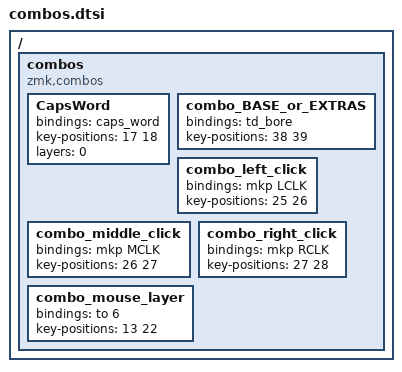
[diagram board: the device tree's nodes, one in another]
/ {
    combos {
        compatible = "zmk,combos";

        CapsWord {
            bindings = <&caps_word>;
            key-positions = <17 18>;
            layers = <0>;
        };

        combo_BASE_or_EXTRAS {
            bindings = <&td_bore>;
            key-positions = <38 39>;
        };
        
        combo_left_click {
            bindings = <&mkp LCLK>;
            key-positions = <25 26>;
        };
        
        combo_middle_click {
            bindings = <&mkp MCLK>;
            key-positions = <26 27>;
        };

        combo_right_click {
            bindings = <&mkp RCLK>;
            key-positions = <27 28>;
        };

        combo_mouse_layer {
            bindings = <&to 6>;
            key-positions = <13 22>;
        };





        // // Left Side Home Row Mods
        // combo_l_cmd {
        //     bindings = <&kp LCMD>;
        //     key-positions = <13 37>;
        //     layers = <0>;
        // };

        // combo_l_alt {
        //     bindings = <&kp LEFT_ALT>;
        //     key-positions = <14 37>;
        //     layers = <0>;
        // };

        // combo_l_ctrl {
        //     bindings = <&kp LCTRL>;
        //     key-positions = <15 37>;
        //     layers = <0>;
        // };

        // combo_l_shift {
        //     bindings = <&kp LEFT_SHIFT>;
        //     key-positions = <16 37>;
        //     layers = <0>;
        // };

        // combo_l_ctrl_alt {
        //     bindings = <&kp LC(LALT)>;
        //     key-positions = <15 15 37>;
        //     layers = <0>;
        // };

        // combo_l_ctrl_shift {
        //     bindings = <&kp LC(LSHFT)>;
        //     key-positions = <15 16 37>;
        //     layers = <0>;
        // };

        // combo_l_ctrl_cmd {
        //     bindings = <&kp LC(LCMD)>;
        //     key-positions = <15 13 37>;
        //     layers = <0>;
        // };

        // combo_l_alt_shift {
        //     bindings = <&kp LA(LSHFT)>;
        //     key-positions = <14 16 37>;
        //     layers = <0>;
        // };

        // combo_l_alt_cmd {
        //     bindings = <&kp LA(LCMD)>;
        //     key-positions = <14 13 37>;
        //     layers = <0>;
        // };

        // combo_l_shift_cmd {
        //     bindings = <&kp LS(LCMD)>;
        //     key-positions = <16 13 37>;
        //     layers = <0>;
        // };

        // combo_l_ctrl_alt_shift {
        //     bindings = <&kp LC(LA(LSHFT))>;
        //     key-positions = <26 37>;
        //     layers = <0>;
        // };

        // combo_l_ctrl_alt_cmd {
        //     bindings = <&kp LC(LA(LCMD))>;
        //     key-positions = <15 14 13 37>;
        //     layers = <0>;
        // };

        // combo_l_ctrl_shift_cmd {
        //     bindings = <&kp LC(LS(LCMD))>;
        //     key-positions = <15 16 13 37>;
        //     layers = <0>;
        // };

        // combo_l_alt_shift_cmd {
        //     bindings = <&kp LA(LS(LCMD))>;
        //     key-positions = <14 16 13 37>;
        //     layers = <0>;
        // };

        // combo_l_ctrl_alt_shift_cmd {
        //     bindings = <&kp LC(LA(LS(LCMD)))>;
        //     key-positions = <27 37>;
        //     layers = <0>;
        // };

        // // Right Side Home Row Mods
        // combo_r_cmd {
        //     bindings = <&kp RCMD>;
        //     key-positions = <22 40>;
        //     layers = <0>;
        // };

        // combo_r_alt {
        //     bindings = <&kp LEFT_ALT>;
        //     key-positions = <21 40>;
        //     layers = <0>;
        // };

        // combo_r_ctrl {
        //     bindings = <&kp RCTRL>;
        //     key-positions = <20 40>;
        //     layers = <0>;
        // };

        // combo_r_shift {
        //     bindings = <&kp RIGHT_SHIFT>;
        //     key-positions = <19 40>;
        //     layers = <0>;
        // };

        // combo_r_ctrl_alt {
        //     bindings = <&kp LC(LALT)>;
        //     key-positions = <20 21 40>;
        //     layers = <0>;
        // };

        // combo_r_ctrl_shift {
        //     bindings = <&kp LC(LSHFT)>;
        //     key-positions = <20 19 40>;
        //     layers = <0>;
        // };

        // combo_r_ctrl_cmd {
        //     bindings = <&kp LC(LCMD)>;
        //     key-positions = <20 22 40>;
        //     layers = <0>;
        // };

        // combo_r_alt_shift {
        //     bindings = <&kp LA(LSHFT)>;
        //     key-positions = <21 19 40>;
        //     layers = <0>;
        // };

        // combo_r_alt_cmd {
        //     bindings = <&kp LA(LCMD)>;
        //     key-positions = <21 22 40>;
        //     layers = <0>;
        // };

        // combo_r_shift_cmd {
        //     bindings = <&kp LS(LCMD)>;
        //     key-positions = <19 22 40>;
        //     layers = <0>;
        // };

        // combo_r_ctrl_alt_shift {
        //     bindings = <&kp LC(LA(LSHFT))>;
        //     key-positions = <33 40>;
        //     layers = <0>;
        // };

        // combo_r_ctrl_alt_cmd {
        //     bindings = <&kp LC(LA(LCMD))>;
        //     key-positions = <20 21 22 40>;
        //     layers = <0>;
        // };

        // combo_r_ctrl_shift_cmd {
        //     bindings = <&kp LC(LS(LCMD))>;
        //     key-positions = <20 19 22 40>;
        //     layers = <0>;
        // };

        // combo_r_alt_shift_cmd {
        //     bindings = <&kp LA(LS(LCMD))>;
        //     key-positions = <21 19 22 40>;
        //     layers = <0>;
        // };

        // combo_r_ctrl_alt_shift_cmd {
        //     bindings = <&kp LC(LA(LS(LCMD)))>;
        //     key-positions = <32 40>;
        //     layers = <0>;
        // };
    };
};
